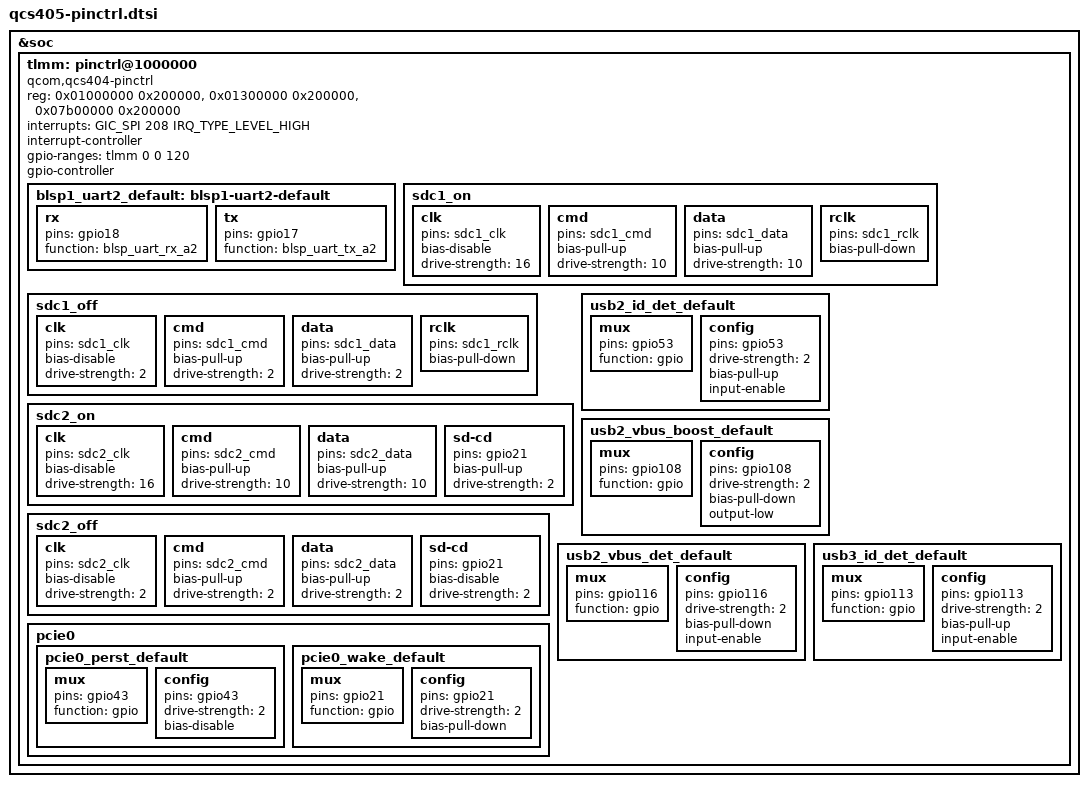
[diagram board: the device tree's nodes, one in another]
&soc {
	tlmm: pinctrl@1000000 {
		compatible = "qcom,qcs404-pinctrl";
		reg = <0x01000000 0x200000>,
		      <0x01300000 0x200000>,
		      <0x07b00000 0x200000>;
		reg-names = "south", "north", "east";
		interrupts = <GIC_SPI 208 IRQ_TYPE_LEVEL_HIGH>;
		interrupt-controller;
		#interrupt-cells = <2>;
		gpio-ranges = <&tlmm 0 0 120>;
		gpio-controller;
		#gpio-cells = <2>;

		blsp1_uart2_default: blsp1-uart2-default {
			rx {
				pins = "gpio18";
				function = "blsp_uart_rx_a2";
			};

			tx {
				pins = "gpio17";
				function = "blsp_uart_tx_a2";
			};
		};

		sdc1_on: sdc1_on {
			clk {
				pins = "sdc1_clk";
				bias-disable;
				drive-strength = <16>;
			};

			cmd {
				pins = "sdc1_cmd";
				bias-pull-up;
				drive-strength = <10>;
			};

			data {
				pins = "sdc1_data";
				bias-pull-up;
				drive-strength = <10>;
			};

			rclk {
				pins = "sdc1_rclk";
				bias-pull-down;
			};
		};

		sdc1_off: sdc1_off {
			clk {
				pins = "sdc1_clk";
				bias-disable;
				drive-strength = <2>;
			};

			cmd {
				pins = "sdc1_cmd";
				bias-pull-up;
				drive-strength = <2>;
			};

			data {
				pins = "sdc1_data";
				bias-pull-up;
				drive-strength = <2>;
			};

			rclk {
				pins = "sdc1_rclk";
				bias-pull-down;
			};
		};

		sdc2_on: sdc2_on {
			clk {
				pins = "sdc2_clk";
				bias-disable;
				drive-strength = <16>;
			};

			cmd {
				pins = "sdc2_cmd";
				bias-pull-up;
				drive-strength = <10>;
			};

			data {
				pins = "sdc2_data";
				bias-pull-up;
				drive-strength = <10>;
			};

			sd-cd {
				pins = "gpio21";
				bias-pull-up;
				drive-strength = <2>;
			};
		};

		sdc2_off: sdc2_off {
			clk {
				pins = "sdc2_clk";
				bias-disable;
				drive-strength = <2>;
			};

			cmd {
				pins = "sdc2_cmd";
				bias-pull-up;
				drive-strength = <2>;
			};

			data {
				pins = "sdc2_data";
				bias-pull-up;
				drive-strength = <2>;
			};

			sd-cd {
				pins = "gpio21";
				bias-disable;
				drive-strength = <2>;
			};
		};
		pcie0 {
			pcie0_perst_default: pcie0_perst_default {
				mux {
					pins = "gpio43";
					function = "gpio";
				};

				config {
					pins = "gpio43";
					drive-strength = <2>;
					bias-disable;
				};
			};

			pcie0_wake_default: pcie0_wake_default {
				mux {
					pins = "gpio21";
					function = "gpio";
				};

				config {
					pins = "gpio21";
					drive-strength = <2>;
					bias-pull-down;
				};
			};
		};

		usb2_id_det_default: usb2_id_det_default {
			mux {
				pins = "gpio53";
				function = "gpio";
			};

			config {
				pins = "gpio53";
				drive-strength = <2>;
				bias-pull-up;
				input-enable;
			};
		};

		usb2_vbus_boost_default: usb2_vbus_boost_default {
			mux {
				pins = "gpio108";
				function = "gpio";
			};

			config {
				pins = "gpio108";
				drive-strength = <2>;
				bias-pull-down;
				output-low;
			};
		};

		usb2_vbus_det_default: usb2_vbus_det_default {
			mux {
				pins = "gpio116";
				function = "gpio";
			};

			config {
				pins = "gpio116";
				drive-strength = <2>;
				bias-pull-down;
				input-enable;
			};
		};

		usb3_id_det_default: usb3_id_det_default {
			mux {
				pins = "gpio113";
				function = "gpio";
			};

			config {
				pins = "gpio113";
				drive-strength = <2>;
				bias-pull-up;
				input-enable;
			};
		};
	};
};
